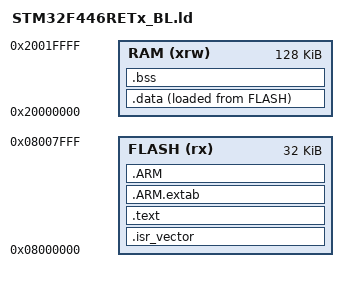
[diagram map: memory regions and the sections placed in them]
/* Bootloader linker script — STM32F446RE
 * Flash sectors 0-1 = 32 KB @ 0x08000000 (bootloader only)
 * SRAM 128 KB @ 0x20000000 */

ENTRY(Reset_Handler)

MEMORY
{
    FLASH (rx)  : ORIGIN = 0x08000000, LENGTH = 32K
    RAM   (xrw) : ORIGIN = 0x20000000, LENGTH = 128K
}

_estack = ORIGIN(RAM) + LENGTH(RAM);

SECTIONS
{
    .isr_vector :
    {
        . = ALIGN(4);
        KEEP(*(.isr_vector))
        . = ALIGN(4);
    } >FLASH

    .text :
    {
        . = ALIGN(4);
        *(.text)
        *(.text*)
        *(.rodata)
        *(.rodata*)
        KEEP(*(.init))
        KEEP(*(.fini))
        . = ALIGN(4);
        _etext = .;
    } >FLASH

    .ARM.extab : { *(.ARM.extab* .gnu.linkonce.armextab.*) } >FLASH
    .ARM        : { __exidx_start = .; *(.ARM.exidx*) __exidx_end = .; } >FLASH

    .data :
    {
        . = ALIGN(4);
        _sdata = .;
        *(.data)
        *(.data*)
        . = ALIGN(4);
        _edata = .;
    } >RAM AT>FLASH

    _sidata = LOADADDR(.data);

    .bss :
    {
        . = ALIGN(4);
        _sbss = .;
        *(.bss)
        *(.bss*)
        *(COMMON)
        . = ALIGN(4);
        _ebss = .;
    } >RAM

    /DISCARD/ : { libc.a(*) libm.a(*) libgcc.a(*) }
}
